# ATSAMG53N19 device description
Architecture: CORTEX-M4; Family: SAMG; Series: SAMG53
Registers are 32-bit, read-write, no defined reset value unless marked. A register's access mark holds for its fields unless they carry their own. Offsets are from the block's base; [hi:lo] are bit positions; 'fields as' and 'values as' point back to an identical list.

## RSTC — Reset Controller
Instances: RSTC 0x400E1400
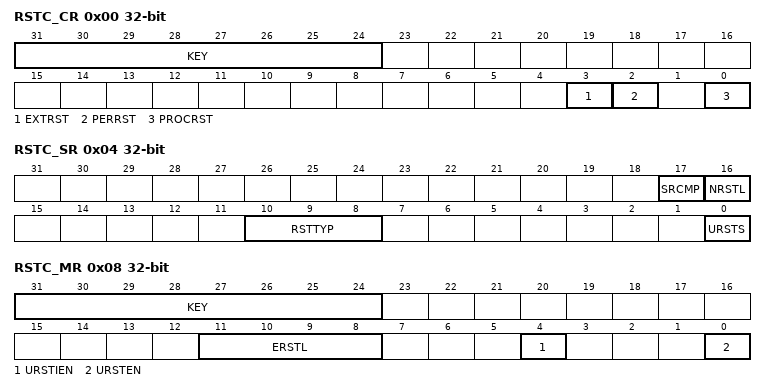
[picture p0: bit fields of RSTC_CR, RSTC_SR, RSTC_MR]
0x00 RSTC_CR wo — Control Register
  [31:24] KEY — System Reset Key
    165=PASSWD (Writing any other value in this field aborts the write operation.)
  [3] EXTRST — External Reset
  [2] PERRST — Peripheral Reset
  [0] PROCRST — Processor Reset
0x04 RSTC_SR ro — Status Register
  [17] SRCMP — Software Reset Command in Progress
  [16] NRSTL — NRST Pin Level
  [10:8] RSTTYP — Reset Type
    0=GENERAL_RST (First power-up reset); 2=WDT_RST (Watchdog fault occurred); 3=SOFT_RST (Processor reset required by the software); 4=USER_RST (NRST pin detected low)
  [0] URSTS — User Reset Status
0x08 RSTC_MR — Mode Register
  [31:24] KEY — Write Access Password
    165=PASSWD (Writing any other value in this field aborts the write operation.Always reads as 0.)
  [11:8] ERSTL — External Reset Length
  [4] URSTIEN — User Reset Interrupt Enable
  [0] URSTEN — User Reset Enable

## RTT — Real-time Timer
Instances: RTT 0x400E1430
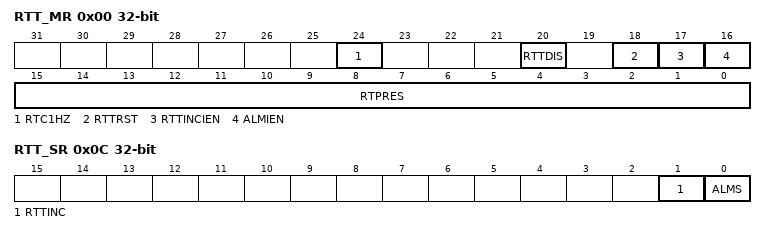
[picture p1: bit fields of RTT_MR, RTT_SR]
0x00 RTT_MR — Mode Register
  [24] RTC1HZ — Real-Time Clock 1Hz Clock Selection
  [20] RTTDIS — Real-time Timer Disable
  [18] RTTRST — Real-time Timer Restart
  [17] RTTINCIEN — Real-time Timer Increment Interrupt Enable
  [16] ALMIEN — Alarm Interrupt Enable
  [15:0] RTPRES — Real-time Timer Prescaler Value
0x04 RTT_AR — Alarm Register
  [31:0] ALMV — Alarm Value
0x08 RTT_VR ro — Value Register
  [31:0] CRTV — Current Real-time Value
0x0C RTT_SR ro — Status Register
  [1] RTTINC — Prescaler Roll-over Status (cleared on read)
  [0] ALMS — Real-time Alarm Status (cleared on read)

## SUPC — Supply Controller
Instances: SUPC 0x400E1410
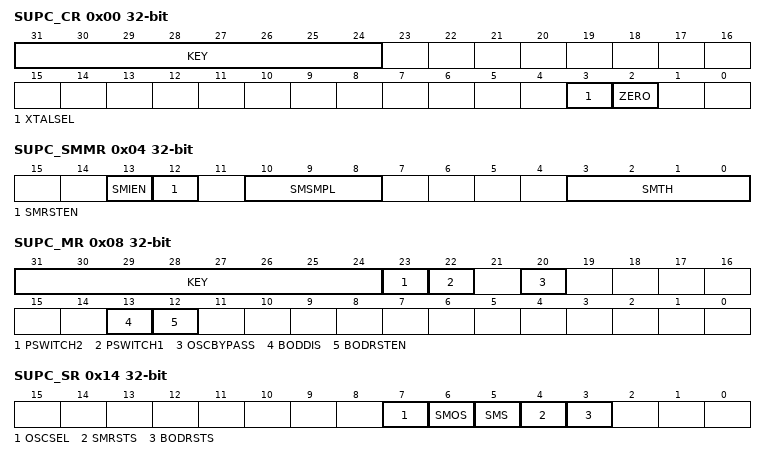
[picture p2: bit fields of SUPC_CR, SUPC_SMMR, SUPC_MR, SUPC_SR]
0x00 SUPC_CR wo — Supply Controller Control Register
  [31:24] KEY — Password
    165=PASSWD (Writing any other value in this field aborts the write operation.Always reads as 0.)
  [3] XTALSEL — Crystal Oscillator Select
    0=NO_EFFECT; 1=CRYSTAL_SEL (If KEY is correct, switches the slow clock on the crystal oscillator output.)
  [2] ZERO — This bit must always be written to 0.
0x04 SUPC_SMMR — Supply Controller Supply Monitor Mode Register
  [13] SMIEN — Supply Monitor Interrupt Enable
    0=NOT_ENABLE (The SUPC interrupt signal is not affected when a supply monitor detection occurs.); 1=ENABLE (The SUPC interrupt signal is asserted when a supply monitor detection occurs.)
  [12] SMRSTEN — Supply Monitor Reset Enable
    0=NOT_ENABLE (The core reset signal vddcore_nreset is not affected when a supply monitor detection occurs.); 1=ENABLE (The core reset signal vddcore_nreset is asserted when a supply monitor detection occurs.)
  [10:8] SMSMPL — Supply Monitor Sampling Period
    0=SMD (Supply Monitor disabled); 1=CSM (Continuous Supply Monitor); 2=_32SLCK (Supply Monitor enables one SLCK period every 32 SLCK periods); 3=_256SLCK (Supply Monitor enables one SLCK period every 256 SLCK periods); 4=_2048SLCK (Supply Monitor enables one SLCK period every 2,048 SLCK periods)
  [3:0] SMTH — Supply Monitor Threshold
0x08 SUPC_MR — Supply Controller Mode Register
  [31:24] KEY — Password Key
    values as SUPC_CR.KEY
  [23] PSWITCH2 — SRAM2 Power Switch
    0=OFF (The SRAM2 is not powered.); 1=ON (The SRAM2 is powered.)
  [22] PSWITCH1 — SRAM1 Power Switch
    0=OFF (The SRAM1 is not powered.); 1=ON (The SRAM1 is powered.)
  [20] OSCBYPASS — Oscillator Bypass
    0=NO_EFFECT (No effect. Clock selection depends on XTALSEL value.); 1=BYPASS (The 32 kHz crystal oscillator is bypassed if XTALSEL=1. OSCBYPASS must be set prior to write XTALSEL=1.)
  [13] BODDIS — POR Core Disable
    0=ENABLE (The core brownout detector is enabled.); 1=DISABLE (The core brownout detector is disabled.)
  [12] BODRSTEN — POR Core Reset Enable
    0=NOT_ENABLE (The core reset signal vddcore_nreset is not affected when a brownout detection occurs.); 1=ENABLE (The core reset signal vddcore_nreset is asserted when a brownout detection occurs.)
0x14 SUPC_SR ro — Supply Controller Status Register
  [7] OSCSEL — 32-kHz Oscillator Selection Status
    0=RC (The slow clock SLCK is generated by the embedded 32 kHz RC oscillator.); 1=CRYST (The slow clock SLCK is generated by the 32 kHz crystal oscillator.)
  [6] SMOS — Supply Monitor Output Status
    0=HIGH (The supply monitor detected VDDIO higher than its threshold at its last measurement.); 1=LOW (The supply monitor detected VDDIO lower than its threshold at its last measurement.)
  [5] SMS — Supply Monitor Status (cleared on read)
    0=NO (No supply monitor detection since the last read of SUPC_SR.); 1=PRESENT (At least one supply monitor detection since the last read of SUPC_SR.)
  [4] SMRSTS — Supply Monitor Reset Status (cleared on read)
    0=NO (No supply monitor detection has generated a core reset since the last read of SUPC_SR.); 1=PRESENT (At least one supply monitor detection has generated a core reset since the last read of SUPC_SR.)
  [3] BODRSTS — Brownout Detector Reset Status (cleared on read)
    0=NO (No core brownout rising edge event has been detected since the last read of SUPC_SR.); 1=PRESENT (At least one brownout output rising edge event has been detected since the last read of SUPC_SR.)

## Notices in the file
Copyright (c) 2017 Microchip Technology Inc.
SPDX-License-Identifier: Apache-2.0
Licensed under the Apache License, Version 2.0 (the "License");
you may not use this file except in compliance with the License.
You may obtain a copy of the License at
http://www.apache.org/licenses/LICENSE-2.0
Unless required by applicable law or agreed to in writing, software
distributed under the License is distributed on an "AS IS" BASIS,
WITHOUT WARRANTIES OR CONDITIONS OF ANY KIND, either express or implied.
See the License for the specific language governing permissions and
limitations under the License.
